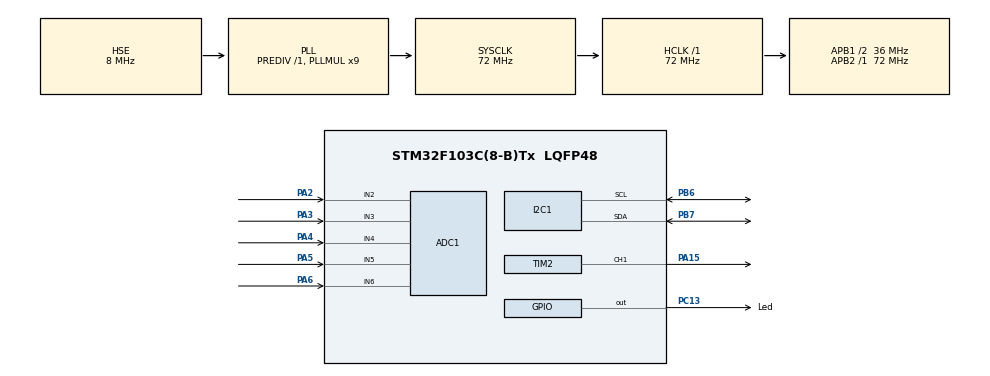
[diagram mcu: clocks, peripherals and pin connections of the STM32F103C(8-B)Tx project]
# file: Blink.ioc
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ADC1.Channel-1\#ChannelRegularConversion=ADC_CHANNEL_2
ADC1.Channel-2\#ChannelRegularConversion=ADC_CHANNEL_3
ADC1.Channel-3\#ChannelRegularConversion=ADC_CHANNEL_4
ADC1.Channel-4\#ChannelRegularConversion=ADC_CHANNEL_5
ADC1.Channel-5\#ChannelRegularConversion=ADC_CHANNEL_6
ADC1.ContinuousConvMode=ENABLE
ADC1.NbrOfConversion=5
ADC1.NbrOfConversionFlag=1
ADC1.Rank-1\#ChannelRegularConversion=1
ADC1.Rank-2\#ChannelRegularConversion=2
ADC1.Rank-3\#ChannelRegularConversion=3
ADC1.Rank-4\#ChannelRegularConversion=4
ADC1.Rank-5\#ChannelRegularConversion=5
ADC1.SamplingTime-1\#ChannelRegularConversion=ADC_SAMPLETIME_239CYCLES_5
ADC1.SamplingTime-2\#ChannelRegularConversion=ADC_SAMPLETIME_239CYCLES_5
ADC1.SamplingTime-3\#ChannelRegularConversion=ADC_SAMPLETIME_239CYCLES_5
ADC1.SamplingTime-4\#ChannelRegularConversion=ADC_SAMPLETIME_239CYCLES_5
ADC1.SamplingTime-5\#ChannelRegularConversion=ADC_SAMPLETIME_239CYCLES_5
ADC1.master=1
Dma.ADC1.0.Direction=DMA_PERIPH_TO_MEMORY
Dma.ADC1.0.Instance=DMA1_Channel1
Dma.ADC1.0.MemDataAlignment=DMA_MDATAALIGN_WORD
Dma.ADC1.0.MemInc=DMA_MINC_ENABLE
Dma.ADC1.0.Mode=DMA_CIRCULAR
Dma.ADC1.0.PeriphDataAlignment=DMA_PDATAALIGN_WORD
Dma.ADC1.0.PeriphInc=DMA_PINC_DISABLE
Dma.ADC1.0.Priority=DMA_PRIORITY_MEDIUM
Dma.I2C1_RX.2.Direction=DMA_PERIPH_TO_MEMORY
Dma.I2C1_RX.2.Instance=DMA1_Channel7
Dma.I2C1_RX.2.MemDataAlignment=DMA_MDATAALIGN_BYTE
Dma.I2C1_RX.2.MemInc=DMA_MINC_ENABLE
Dma.I2C1_RX.2.Mode=DMA_NORMAL
Dma.I2C1_RX.2.PeriphDataAlignment=DMA_PDATAALIGN_BYTE
Dma.I2C1_RX.2.PeriphInc=DMA_PINC_DISABLE
Dma.I2C1_RX.2.Priority=DMA_PRIORITY_LOW
Dma.Request0=ADC1
Dma.Request1=TIM2_CH1
Dma.Request2=I2C1_RX
Dma.TIM2_CH1.1.Direction=DMA_MEMORY_TO_PERIPH
Dma.TIM2_CH1.1.Instance=DMA1_Channel5
Dma.TIM2_CH1.1.MemDataAlignment=DMA_MDATAALIGN_HALFWORD
Dma.TIM2_CH1.1.MemInc=DMA_MINC_ENABLE
Dma.TIM2_CH1.1.Mode=DMA_NORMAL
Dma.TIM2_CH1.1.PeriphDataAlignment=DMA_PDATAALIGN_HALFWORD
Dma.TIM2_CH1.1.PeriphInc=DMA_PINC_DISABLE
Dma.TIM2_CH1.1.Priority=DMA_PRIORITY_MEDIUM
I2C1.I2C_Mode=I2C_Fast
I2C1.OwnAddress=0x24
Mcu.Family=STM32F1
Mcu.Name=STM32F103C(8-B)Tx
Mcu.Package=LQFP48
NVIC.DMA1_Channel1_IRQn=true\:0\:0\:false\:false\:true\:false\:true
NVIC.DMA1_Channel5_IRQn=true\:0\:0\:false\:false\:true\:false\:true
NVIC.DMA1_Channel7_IRQn=true\:0\:0\:false\:false\:true\:false\:true
NVIC.I2C1_ER_IRQn=true\:0\:0\:false\:false\:true\:true\:true
NVIC.I2C1_EV_IRQn=true\:0\:0\:false\:false\:true\:true\:true
NVIC.PriorityGroup=NVIC_PRIORITYGROUP_4
NVIC.TIM3_IRQn=true\:0\:0\:false\:false\:true\:true\:true
NVIC.TIM4_IRQn=true\:0\:0\:false\:false\:true\:true\:true
PA13.Mode=Serial_Wire
PA13.Signal=SYS_JTMS-SWDIO
PA14.Mode=Serial_Wire
PA14.Signal=SYS_JTCK-SWCLK
PA15.GPIO_Speed=GPIO_SPEED_FREQ_HIGH
PA15.Signal=S_TIM2_CH1_ETR
PA2.Signal=ADCx_IN2
PA3.Signal=ADCx_IN3
PA4.Signal=ADCx_IN4
PA5.Signal=ADCx_IN5
PA6.Signal=ADCx_IN6
PB6.Mode=I2C
PB6.Signal=I2C1_SCL
PB7.Mode=I2C
PB7.Signal=I2C1_SDA
PC13-TAMPER-RTC.GPIO_Label=Led
PC13-TAMPER-RTC.Signal=GPIO_Output
PD0-OSC_IN.Mode=HSE-External-Oscillator
PD0-OSC_IN.Signal=RCC_OSC_IN
PD1-OSC_OUT.Mode=HSE-External-Oscillator
PD1-OSC_OUT.Signal=RCC_OSC_OUT
ProjectManager.HeapSize=0x200
ProjectManager.StackSize=0x400
ProjectManager.TargetToolchain=STM32CubeIDE
RCC.ADCPresc=RCC_ADCPCLK2_DIV6
RCC.AHBFreq_Value=72000000
RCC.APB1CLKDivider=RCC_HCLK_DIV2
RCC.APB1Freq_Value=36000000
RCC.APB1TimFreq_Value=72000000
RCC.APB2Freq_Value=72000000
RCC.APB2TimFreq_Value=72000000
RCC.HCLKFreq_Value=72000000
RCC.PLLMUL=RCC_PLL_MUL9
RCC.PLLSourceVirtual=RCC_PLLSOURCE_HSE
RCC.PREFETCH_ENABLE=1
RCC.SYSCLKFreq_VALUE=72000000
RCC.SYSCLKSource=RCC_SYSCLKSOURCE_PLLCLK
RCC.USBFreq_Value=48000000
RCC.USBPrescaler=RCC_USBCLKSOURCE_PLL_DIV1_5
SH.ADCx_IN2.0=ADC1_IN2,IN2
SH.ADCx_IN3.0=ADC1_IN3,IN3
SH.ADCx_IN4.0=ADC1_IN4,IN4
SH.ADCx_IN5.0=ADC1_IN5,IN5
SH.ADCx_IN6.0=ADC1_IN6,IN6
SH.S_TIM2_CH1_ETR.0=TIM2_CH1,PWM Generation1 CH1
TIM2.Channel-PWM\ Generation1\ CH1=TIM_CHANNEL_1
TIM2.OCFastMode_PWM-PWM\ Generation1\ CH1=TIM_OCFAST_DISABLE
TIM2.OCMode_PWM-PWM\ Generation1\ CH1=TIM_OCMODE_PWM1
TIM2.Period=90-1
TIM2.Prescaler=0
TIM3.Period=2-1
TIM3.Prescaler=36000-1
TIM4.Period=200-1
TIM4.Prescaler=36000-1
VP_TIM2_VS_ClockSourceINT.Mode=Internal
VP_TIM3_VS_ClockSourceINT.Mode=Internal
VP_TIM4_VS_ClockSourceINT.Mode=Internal
board=custom

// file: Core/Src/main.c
/* USER CODE BEGIN Header */
/**
  ******************************************************************************
  * @file           : main.c
  * @brief          : Main program body
  ******************************************************************************
  * @attention
  *
  * <h2><center>&copy; Copyright (c) 2021 STMicroelectronics.
  * All rights reserved.</center></h2>
  *
  * This software component is licensed by ST under BSD 3-Clause license,
  * the "License"; You may not use this file except in compliance with the
  * License. You may obtain a copy of the License at:
  *                        opensource.org/licenses/BSD-3-Clause
  *
  ******************************************************************************
  */
/* USER CODE END Header */
#include "main.h"

/* USER CODE BEGIN Includes */
#include <cppmain.h>
/* USER CODE END Includes */

ADC_HandleTypeDef hadc1;
DMA_HandleTypeDef hdma_adc1;

I2C_HandleTypeDef hi2c1;
DMA_HandleTypeDef hdma_i2c1_rx;

TIM_HandleTypeDef htim2;
TIM_HandleTypeDef htim3;
TIM_HandleTypeDef htim4;
DMA_HandleTypeDef hdma_tim2_ch1;

void SystemClock_Config(void);
static void MX_GPIO_Init(void);
static void MX_DMA_Init(void);
static void MX_I2C1_Init(void);
static void MX_ADC1_Init(void);
static void MX_TIM2_Init(void);
static void MX_TIM3_Init(void);
static void MX_TIM4_Init(void);

int main(void)
{

  /* MCU Configuration--------------------------------------------------------*/

  /* Reset of all peripherals, Initializes the Flash interface and the Systick. */
  HAL_Init();

  /* Configure the system clock */
  SystemClock_Config();

  /* USER CODE BEGIN SysInit */
  __HAL_RCC_I2C1_CLK_ENABLE();
   HAL_Delay(100);
   __HAL_RCC_I2C1_FORCE_RESET();
   HAL_Delay(100);
   __HAL_RCC_I2C1_RELEASE_RESET();
   HAL_Delay(100);
  /* USER CODE END SysInit */

  /* Initialize all configured peripherals */
  MX_GPIO_Init();
  MX_DMA_Init();
  MX_I2C1_Init();
  MX_ADC1_Init();
  MX_TIM2_Init();
  MX_TIM3_Init();
  MX_TIM4_Init();

  /* Infinite loop */
  /* USER CODE BEGIN WHILE */

  cppmain();
  while (1)
  {

    /* USER CODE END WHILE */

    /* USER CODE BEGIN 3 */
	  /*if(flag == 1)
	  {
		  flag = 0;
		  snprintf(trans_str, 63, "ADC %d %d %d %d %d\n", (uint16_t)adc[0], (uint16_t)adc[1], (uint16_t)adc[2], (uint16_t)adc[3], (uint16_t)adc[4]);

		  CDC_Transmit_FS(trans_str, sizeof(trans_str));
	  }*/

  }
  /* USER CODE END 3 */
}

void SystemClock_Config(void)
{
  RCC_OscInitTypeDef RCC_OscInitStruct = {0};
  RCC_ClkInitTypeDef RCC_ClkInitStruct = {0};
  RCC_PeriphCLKInitTypeDef PeriphClkInit = {0};

  /** Initializes the RCC Oscillators according to the specified parameters
  * in the RCC_OscInitTypeDef structure.
  */
  RCC_OscInitStruct.OscillatorType = RCC_OSCILLATORTYPE_HSE;
  RCC_OscInitStruct.HSEState = RCC_HSE_ON;
  RCC_OscInitStruct.HSEPredivValue = RCC_HSE_PREDIV_DIV1;
  RCC_OscInitStruct.HSIState = RCC_HSI_ON;
  RCC_OscInitStruct.PLL.PLLState = RCC_PLL_ON;
  RCC_OscInitStruct.PLL.PLLSource = RCC_PLLSOURCE_HSE;
  RCC_OscInitStruct.PLL.PLLMUL = RCC_PLL_MUL9;
  if (HAL_RCC_OscConfig(&RCC_OscInitStruct) != HAL_OK)
  {
    Error_Handler();
  }
  /** Initializes the CPU, AHB and APB buses clocks
  */
  RCC_ClkInitStruct.ClockType = RCC_CLOCKTYPE_HCLK|RCC_CLOCKTYPE_SYSCLK
                              |RCC_CLOCKTYPE_PCLK1|RCC_CLOCKTYPE_PCLK2;
  RCC_ClkInitStruct.SYSCLKSource = RCC_SYSCLKSOURCE_PLLCLK;
  RCC_ClkInitStruct.AHBCLKDivider = RCC_SYSCLK_DIV1;
  RCC_ClkInitStruct.APB1CLKDivider = RCC_HCLK_DIV2;
  RCC_ClkInitStruct.APB2CLKDivider = RCC_HCLK_DIV1;

  if (HAL_RCC_ClockConfig(&RCC_ClkInitStruct, FLASH_LATENCY_2) != HAL_OK)
  {
    Error_Handler();
  }
  PeriphClkInit.PeriphClockSelection = RCC_PERIPHCLK_ADC;
  PeriphClkInit.AdcClockSelection = RCC_ADCPCLK2_DIV6;
  if (HAL_RCCEx_PeriphCLKConfig(&PeriphClkInit) != HAL_OK)
  {
    Error_Handler();
  }
}

static void MX_ADC1_Init(void)
{

  ADC_ChannelConfTypeDef sConfig = {0};

  /** Common config
  */
  hadc1.Instance = ADC1;
  hadc1.Init.ScanConvMode = ADC_SCAN_ENABLE;
  hadc1.Init.ContinuousConvMode = ENABLE;
  hadc1.Init.DiscontinuousConvMode = DISABLE;
  hadc1.Init.ExternalTrigConv = ADC_SOFTWARE_START;
  hadc1.Init.DataAlign = ADC_DATAALIGN_RIGHT;
  hadc1.Init.NbrOfConversion = 5;
  if (HAL_ADC_Init(&hadc1) != HAL_OK)
  {
    Error_Handler();
  }
  /** Configure Regular Channel
  */
  sConfig.Channel = ADC_CHANNEL_2;
  sConfig.Rank = ADC_REGULAR_RANK_1;
  sConfig.SamplingTime = ADC_SAMPLETIME_239CYCLES_5;
  if (HAL_ADC_ConfigChannel(&hadc1, &sConfig) != HAL_OK)
  {
    Error_Handler();
  }
  /** Configure Regular Channel
  */
  sConfig.Channel = ADC_CHANNEL_3;
  sConfig.Rank = ADC_REGULAR_RANK_2;
  if (HAL_ADC_ConfigChannel(&hadc1, &sConfig) != HAL_OK)
  {
    Error_Handler();
  }
  /** Configure Regular Channel
  */
  sConfig.Channel = ADC_CHANNEL_4;
  sConfig.Rank = ADC_REGULAR_RANK_3;
  if (HAL_ADC_ConfigChannel(&hadc1, &sConfig) != HAL_OK)
  {
    Error_Handler();
  }
  /** Configure Regular Channel
  */
  sConfig.Channel = ADC_CHANNEL_5;
  sConfig.Rank = ADC_REGULAR_RANK_4;
  if (HAL_ADC_ConfigChannel(&hadc1, &sConfig) != HAL_OK)
  {
    Error_Handler();
  }
  /** Configure Regular Channel
  */
  sConfig.Channel = ADC_CHANNEL_6;
  sConfig.Rank = ADC_REGULAR_RANK_5;
  if (HAL_ADC_ConfigChannel(&hadc1, &sConfig) != HAL_OK)
  {
    Error_Handler();
  }

}

static void MX_I2C1_Init(void)
{

  hi2c1.Instance = I2C1;
  hi2c1.Init.ClockSpeed = 400000;
  hi2c1.Init.DutyCycle = I2C_DUTYCYCLE_2;
  hi2c1.Init.OwnAddress1 = 72;
  hi2c1.Init.AddressingMode = I2C_ADDRESSINGMODE_7BIT;
  hi2c1.Init.DualAddressMode = I2C_DUALADDRESS_DISABLE;
  hi2c1.Init.OwnAddress2 = 0;
  hi2c1.Init.GeneralCallMode = I2C_GENERALCALL_DISABLE;
  hi2c1.Init.NoStretchMode = I2C_NOSTRETCH_DISABLE;
  if (HAL_I2C_Init(&hi2c1) != HAL_OK)
  {
    Error_Handler();
  }

}

static void MX_TIM2_Init(void)
{

  TIM_ClockConfigTypeDef sClockSourceConfig = {0};
  TIM_MasterConfigTypeDef sMasterConfig = {0};
  TIM_OC_InitTypeDef sConfigOC = {0};

  htim2.Instance = TIM2;
  htim2.Init.Prescaler = 0;
  htim2.Init.CounterMode = TIM_COUNTERMODE_UP;
  htim2.Init.Period = 90-1;
  htim2.Init.ClockDivision = TIM_CLOCKDIVISION_DIV1;
  htim2.Init.AutoReloadPreload = TIM_AUTORELOAD_PRELOAD_DISABLE;
  if (HAL_TIM_Base_Init(&htim2) != HAL_OK)
  {
    Error_Handler();
  }
  sClockSourceConfig.ClockSource = TIM_CLOCKSOURCE_INTERNAL;
  if (HAL_TIM_ConfigClockSource(&htim2, &sClockSourceConfig) != HAL_OK)
  {
    Error_Handler();
  }
  if (HAL_TIM_PWM_Init(&htim2) != HAL_OK)
  {
    Error_Handler();
  }
  sMasterConfig.MasterOutputTrigger = TIM_TRGO_RESET;
  sMasterConfig.MasterSlaveMode = TIM_MASTERSLAVEMODE_DISABLE;
  if (HAL_TIMEx_MasterConfigSynchronization(&htim2, &sMasterConfig) != HAL_OK)
  {
    Error_Handler();
  }
  sConfigOC.OCMode = TIM_OCMODE_PWM1;
  sConfigOC.Pulse = 0;
  sConfigOC.OCPolarity = TIM_OCPOLARITY_HIGH;
  sConfigOC.OCFastMode = TIM_OCFAST_DISABLE;
  if (HAL_TIM_PWM_ConfigChannel(&htim2, &sConfigOC, TIM_CHANNEL_1) != HAL_OK)
  {
    Error_Handler();
  }
  HAL_TIM_MspPostInit(&htim2);

}

static void MX_TIM3_Init(void)
{

  TIM_ClockConfigTypeDef sClockSourceConfig = {0};
  TIM_MasterConfigTypeDef sMasterConfig = {0};

  htim3.Instance = TIM3;
  htim3.Init.Prescaler = 36000-1;
  htim3.Init.CounterMode = TIM_COUNTERMODE_UP;
  htim3.Init.Period = 2-1;
  htim3.Init.ClockDivision = TIM_CLOCKDIVISION_DIV1;
  htim3.Init.AutoReloadPreload = TIM_AUTORELOAD_PRELOAD_DISABLE;
  if (HAL_TIM_Base_Init(&htim3) != HAL_OK)
  {
    Error_Handler();
  }
  sClockSourceConfig.ClockSource = TIM_CLOCKSOURCE_INTERNAL;
  if (HAL_TIM_ConfigClockSource(&htim3, &sClockSourceConfig) != HAL_OK)
  {
    Error_Handler();
  }
  sMasterConfig.MasterOutputTrigger = TIM_TRGO_RESET;
  sMasterConfig.MasterSlaveMode = TIM_MASTERSLAVEMODE_DISABLE;
  if (HAL_TIMEx_MasterConfigSynchronization(&htim3, &sMasterConfig) != HAL_OK)
  {
    Error_Handler();
  }

}

static void MX_TIM4_Init(void)
{

  TIM_ClockConfigTypeDef sClockSourceConfig = {0};
  TIM_MasterConfigTypeDef sMasterConfig = {0};

  htim4.Instance = TIM4;
  htim4.Init.Prescaler = 36000-1;
  htim4.Init.CounterMode = TIM_COUNTERMODE_UP;
  htim4.Init.Period = 200-1;
  htim4.Init.ClockDivision = TIM_CLOCKDIVISION_DIV1;
  htim4.Init.AutoReloadPreload = TIM_AUTORELOAD_PRELOAD_DISABLE;
  if (HAL_TIM_Base_Init(&htim4) != HAL_OK)
  {
    Error_Handler();
  }
  sClockSourceConfig.ClockSource = TIM_CLOCKSOURCE_INTERNAL;
  if (HAL_TIM_ConfigClockSource(&htim4, &sClockSourceConfig) != HAL_OK)
  {
    Error_Handler();
  }
  sMasterConfig.MasterOutputTrigger = TIM_TRGO_RESET;
  sMasterConfig.MasterSlaveMode = TIM_MASTERSLAVEMODE_DISABLE;
  if (HAL_TIMEx_MasterConfigSynchronization(&htim4, &sMasterConfig) != HAL_OK)
  {
    Error_Handler();
  }

}

static void MX_DMA_Init(void)
{

  /* DMA controller clock enable */
  __HAL_RCC_DMA1_CLK_ENABLE();

  /* DMA interrupt init */
  /* DMA1_Channel1_IRQn interrupt configuration */
  HAL_NVIC_SetPriority(DMA1_Channel1_IRQn, 0, 0);
  HAL_NVIC_EnableIRQ(DMA1_Channel1_IRQn);
  /* DMA1_Channel5_IRQn interrupt configuration */
  HAL_NVIC_SetPriority(DMA1_Channel5_IRQn, 0, 0);
  HAL_NVIC_EnableIRQ(DMA1_Channel5_IRQn);
  /* DMA1_Channel7_IRQn interrupt configuration */
  HAL_NVIC_SetPriority(DMA1_Channel7_IRQn, 0, 0);
  HAL_NVIC_EnableIRQ(DMA1_Channel7_IRQn);

}

static void MX_GPIO_Init(void)
{
  GPIO_InitTypeDef GPIO_InitStruct = {0};

  /* GPIO Ports Clock Enable */
  __HAL_RCC_GPIOC_CLK_ENABLE();
  __HAL_RCC_GPIOD_CLK_ENABLE();
  __HAL_RCC_GPIOA_CLK_ENABLE();
  __HAL_RCC_GPIOB_CLK_ENABLE();

  /*Configure GPIO pin Output Level */
  HAL_GPIO_WritePin(Led_GPIO_Port, Led_Pin, GPIO_PIN_RESET);

  /*Configure GPIO pin : Led_Pin */
  GPIO_InitStruct.Pin = Led_Pin;
  GPIO_InitStruct.Mode = GPIO_MODE_OUTPUT_PP;
  GPIO_InitStruct.Pull = GPIO_NOPULL;
  GPIO_InitStruct.Speed = GPIO_SPEED_FREQ_LOW;
  HAL_GPIO_Init(Led_GPIO_Port, &GPIO_InitStruct);

}

void Error_Handler(void)
{
  __disable_irq();
  while (1)
  {
  }
}

/************************ (C) COPYRIGHT STMicroelectronics *****END OF FILE****/
